# MPS2_AN385 register map
Arm MPS2 AN385, Cortex-M3 (sous-ensemble pour gdbtrace)
Registers are 32-bit, read-write, reset 0x0 unless marked. A register's access mark holds for its fields unless they carry their own. Offsets are from the block's base; lines under a group give offsets from that group; [hi:lo] are bit positions; {n}, {i} and the like mark numbered series; 'fields as' and 'values as' point back to an identical list; <NAME> marks a mode.

## Memory map
0x40000000 TIMER0 — CMSDK APB timer 0
0x40001000 TIMER1 — CMSDK APB timer 1
0x40004000 UART0 — CMSDK APB UART 0
0xE000E010 SysTick — Timer système du cœur Cortex-M
0xE000ED00 SCB — System Control Block

## TIMER0 — CMSDK APB timer 0
Base 0x40000000
Same registers: TIMER1 0x40001000
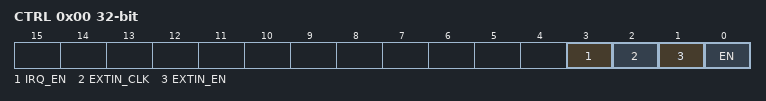
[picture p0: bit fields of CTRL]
0x00 CTRL — Control
  [3] IRQ_EN — Interrupt enable
  [2] EXTIN_CLK — External input as clock
  [1] EXTIN_EN — External input as enable
  [0] EN — Timer enable
    0=DISABLED; 1=ENABLED
0x04 VALUE — Current value (décompte)
0x08 RELOAD — Reload value
0x0C INTSTATUS — Interrupt status (écriture de 1 : INTCLEAR)
  [0] IRQ

## UART0 — CMSDK APB UART 0
Base 0x40004000
0x00 DATA read-modifies — Données RX/TX (la lecture dépile la FIFO de réception)
  [7:0] DATA
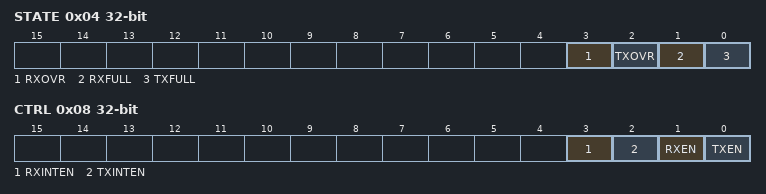
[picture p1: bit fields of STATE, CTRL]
0x04 STATE — État
  [3] RXOVR, [2] TXOVR, [1] RXFULL, [0] TXFULL
0x08 CTRL — Contrôle
  [3] RXINTEN, [2] TXINTEN, [1] RXEN, [0] TXEN
0x0C INTSTATUS — Interrupt status / clear
0x10 BAUDDIV — Diviseur de baud
  [19:0] BAUDDIV

## SysTick — Timer système du cœur Cortex-M
Base 0xE000E010
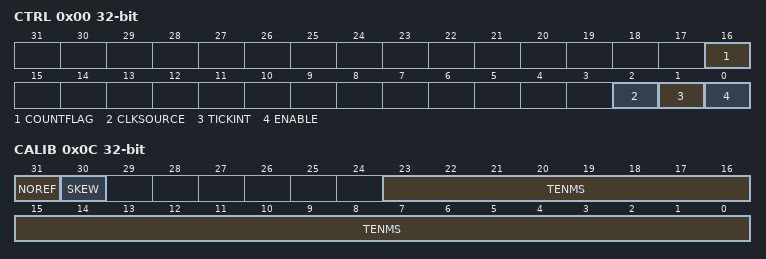
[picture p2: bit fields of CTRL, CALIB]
0x00 CTRL — SysTick Control and Status
  [16] COUNTFLAG ro — Repasse à 0 à la lecture
  [2] CLKSOURCE
    0=EXTERNAL; 1=PROCESSOR
  [1] TICKINT
  [0] ENABLE
0x04 LOAD — Reload value
  [23:0] RELOAD
0x08 VAL — Current value
  [23:0] CURRENT
0x0C CALIB ro — Calibration
  [31] NOREF, [30] SKEW, [23:0] TENMS

## SCB — System Control Block
Base 0xE000ED00
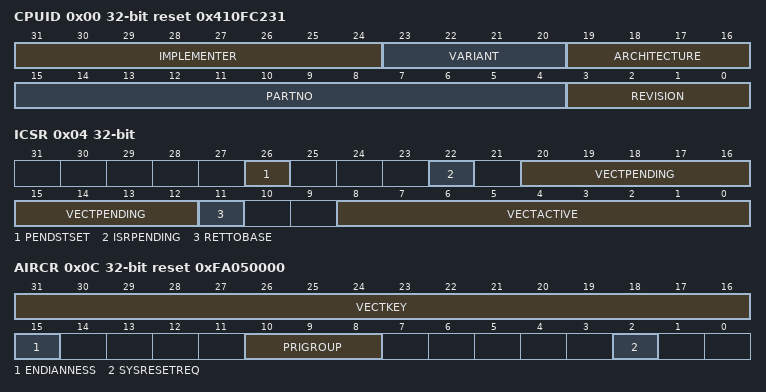
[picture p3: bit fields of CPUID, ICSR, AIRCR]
0x00 CPUID ro reset 0x410FC231
  [31:24] IMPLEMENTER
    65=ARM
  [23:20] VARIANT
  [19:16] ARCHITECTURE
  [15:4] PARTNO
    0xC20=CORTEX_M0; 0xC23=CORTEX_M3; 0xC24=CORTEX_M4; 0xC27=CORTEX_M7
  [3:0] REVISION
0x04 ICSR — Interrupt Control and State
  [26] PENDSTSET, [22] ISRPENDING ro, [20:12] VECTPENDING ro, [11] RETTOBASE ro, [8:0] VECTACTIVE ro
0x08 VTOR — Vector Table Offset
0x0C AIRCR reset 0xFA050000 — Application Interrupt and Reset Control
  [31:16] VECTKEY
  [15] ENDIANNESS
    0=LITTLE; 1=BIG
  [10:8] PRIGROUP
  [2] SYSRESETREQ wo
{0x14+4i} SHPR{i} (i=1..3) — System Handler Priority
